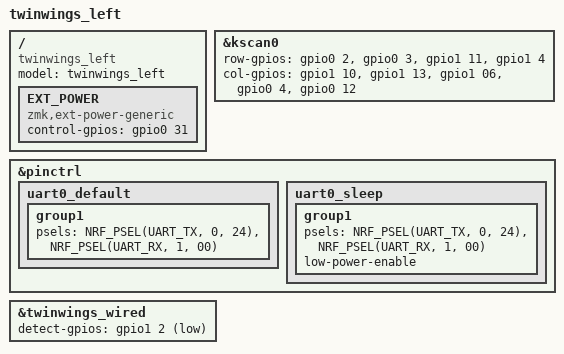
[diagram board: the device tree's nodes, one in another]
/*
 * Copyright (c) 2026 Nicolas Munnich
 * SPDX-License-Identifier: MIT
 */

#include "twinwings.dtsi"

/ {
    model = "twinwings_left";
    compatible = "twinwings_left";

    EXT_POWER {
        compatible = "zmk,ext-power-generic";
        control-gpios = <&gpio0 31 GPIO_ACTIVE_HIGH>;
    };
};

&kscan0 {
    row-gpios
        = <&gpio0 2 (GPIO_ACTIVE_HIGH | GPIO_PULL_DOWN)>
        , <&gpio0 3 (GPIO_ACTIVE_HIGH | GPIO_PULL_DOWN)>
        , <&gpio1 11 (GPIO_ACTIVE_HIGH | GPIO_PULL_DOWN)>
        , <&gpio1 4 (GPIO_ACTIVE_HIGH | GPIO_PULL_DOWN)>
        ;
    col-gpios
        = <&gpio1 10 GPIO_ACTIVE_HIGH>
        , <&gpio1 13 GPIO_ACTIVE_HIGH>
        , <&gpio1 06 GPIO_ACTIVE_HIGH>
        , <&gpio0 4 GPIO_ACTIVE_HIGH>
        , <&gpio0 12 GPIO_ACTIVE_HIGH>
        ;
};

&pinctrl {
    uart0_default: uart0_default {
        group1 {
            psels = <NRF_PSEL(UART_TX, 0, 24)>, 
                    <NRF_PSEL(UART_RX, 1, 00)>; 
        };
    };

    uart0_sleep: uart0_sleep {
        group1 {
            psels = <NRF_PSEL(UART_TX, 0, 24)>,
                    <NRF_PSEL(UART_RX, 1, 00)>;
            low-power-enable;
        };
    };
};

&twinwings_wired {
    detect-gpios = <&gpio1 2 (GPIO_ACTIVE_LOW | GPIO_PULL_UP)>;
};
